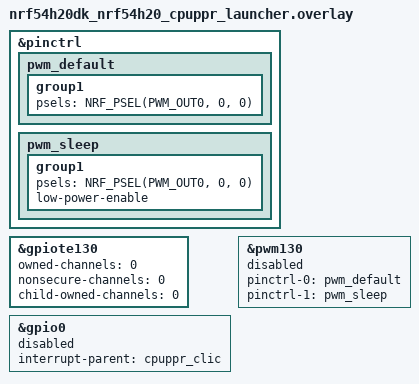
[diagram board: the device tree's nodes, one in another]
/*
 * Copyright (c) 2024 Nordic Semiconductor ASA
 *
 * SPDX-License-Identifier: LicenseRef-Nordic-5-Clause
 */

&pinctrl {
	pwm_default: pwm_default {
		group1 {
			psels = <NRF_PSEL(PWM_OUT0, 0, 0)>;
		};
	};
	pwm_sleep: pwm_sleep {
		group1 {
			psels = <NRF_PSEL(PWM_OUT0, 0, 0)>;
			low-power-enable;
		};
	};
};

&gpiote130 {
	owned-channels = < 0 >;
	nonsecure-channels = < 0 >;
	child-owned-channels = < 0 >;
};

&gpio0 {
	status = "reserved";
	interrupt-parent = <&cpuppr_clic>;
};

&pwm130 {
	status = "reserved";
	pinctrl-0 = <&pwm_default>;
	pinctrl-1 = <&pwm_sleep>;
	pinctrl-names = "default", "sleep";
};
